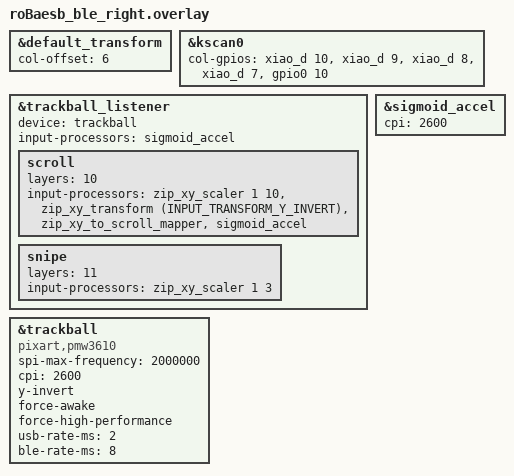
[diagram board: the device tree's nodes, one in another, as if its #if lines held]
#include "../roBa/roBa.dtsi"
#include "../roBa/roBa_R_trackball.dtsi"
#ifdef ZMK_ESB_ADDR_B
#include "roBaesb_addr_b.dtsi"
#else
#include "roBaesb_ble_addr.dtsi"
#endif
#include <input/processors/xyz.dtsi>
#include <behaviors/input_processor_sigmoid_accel.dtsi>


&default_transform {
    col-offset = <6>;
};

&kscan0 {
    col-gpios
        = <&xiao_d 10 GPIO_ACTIVE_HIGH>
        , <&xiao_d 9 GPIO_ACTIVE_HIGH>
        , <&xiao_d 8 GPIO_ACTIVE_HIGH>
        , <&xiao_d 7 GPIO_ACTIVE_HIGH>
        , <&gpio0 10 GPIO_ACTIVE_HIGH>
        ;
};

&trackball_listener {
    status = "okay";
    device = <&trackball>;
    input-processors = <&sigmoid_accel>;

    scroll {
        layers = <10>;
        input-processors = <&zip_xy_scaler 1 10>, <&zip_xy_transform (INPUT_TRANSFORM_Y_INVERT)>, <&zip_xy_to_scroll_mapper>, <&sigmoid_accel>;
    };

    snipe {
        layers = <11>;
        input-processors = <&zip_xy_scaler 1 3>;
    };
};

&sigmoid_accel {
    cpi = <2600>;
};

&trackball {
    compatible = "pixart,pmw3610";
    spi-max-frequency = <2000000>;
    cpi = <2600>;
    y-invert;
    force-awake;
    force-high-performance;
    usb-rate-ms = <2>;
    ble-rate-ms = <8>;
    /delete-property/ invert-y;
};
